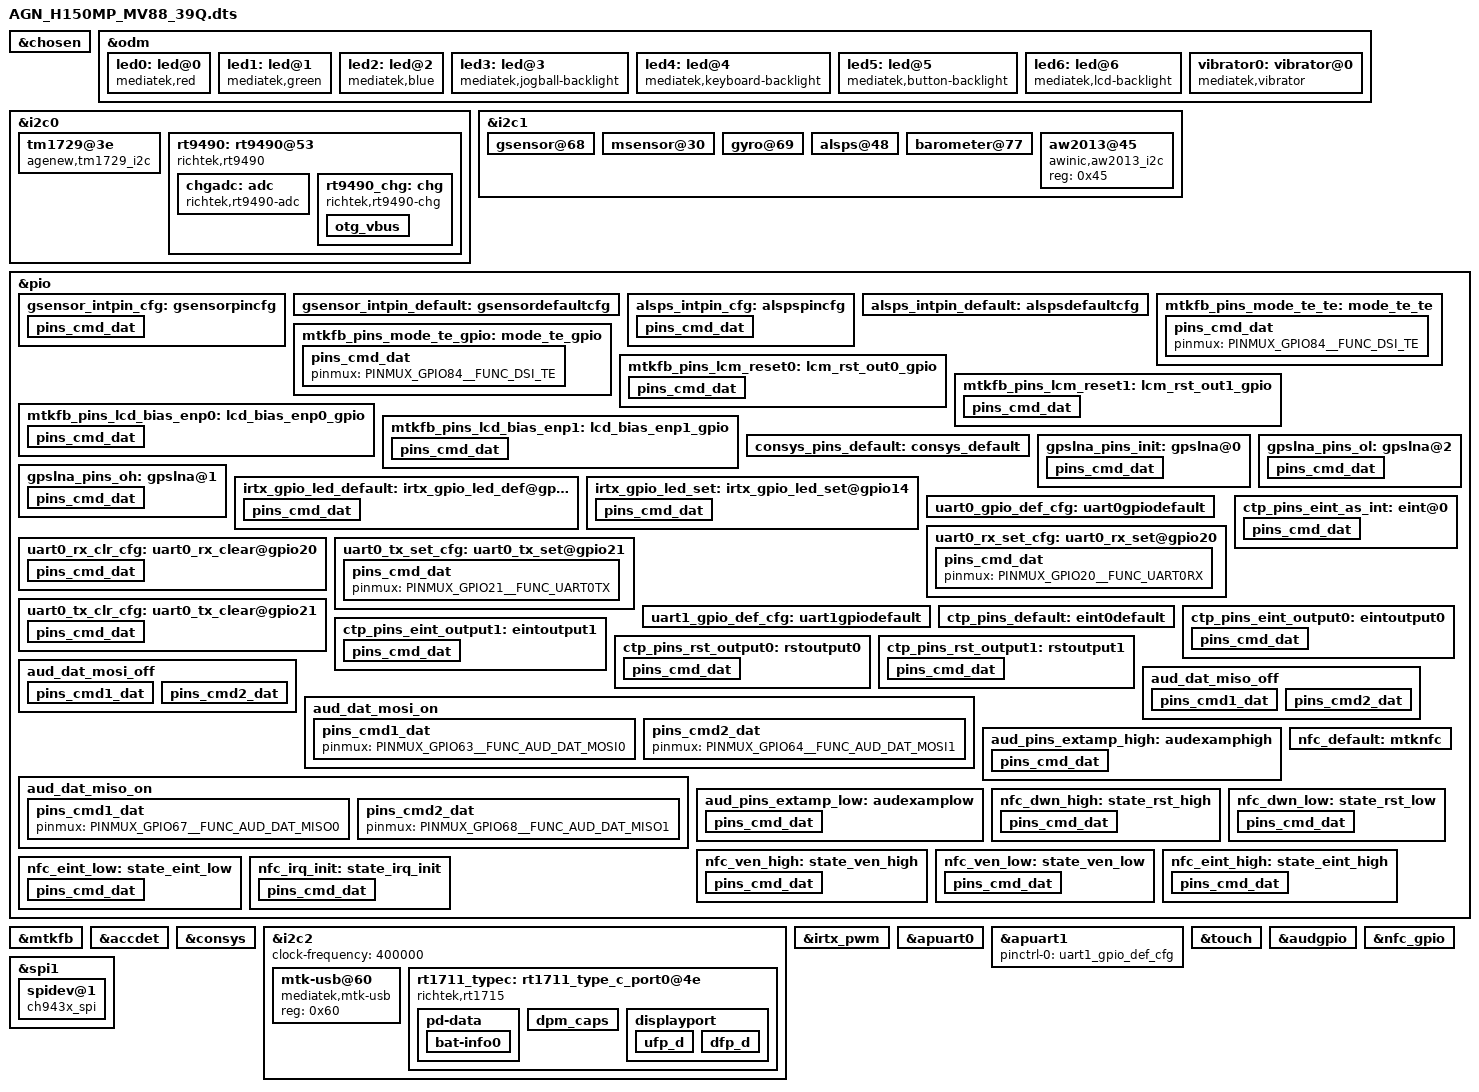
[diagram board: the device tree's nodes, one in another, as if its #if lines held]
/*
 * Mediatek's MT6739 SoC device tree source
 *
 * Copyright (C) 2016 MediaTek Inc.
 *
 * This program is free software; you can redistribute it and/or modify
 * it under the terms of the GNU General Public License version 2 as
 * published by the Free Software Foundation.
 *
 * This program is distributed in the hope that it will be useful,
 * but WITHOUT ANY WARRANTY; without even the implied warranty of
 * MERCHANTABILITY or FITNESS FOR A PARTICULAR PURPOSE.
 * See http://www.gnu.org/licenses/gpl-2.0.html for more details.
 */
#include <generated/autoconf.h>
/dts-v1/;

/plugin/;
#include <dt-bindings/mmc/mt6739-msdc.h>
#include <dt-bindings/iio/adc/richtek,rt9490-adc.h>
#include <dt-bindings/pinctrl/mt6739-pinfunc.h>
#include <dt-bindings/interrupt-controller/irq.h>
#include <dt-bindings/mfd/richtek,rt9490.h>
#include <dt-bindings/interrupt-controller/arm-gic.h>
#include <dt-bindings/gpio/gpio.h>

#define __THIS_PIN_IS_UNUSED_GPIO_NUM__                  (2)   //The board does not use this GPIO
#define __THIS_PIN_IS_UNUSED_GPIO__                      PINMUX_GPIO2__FUNC_GPIO2 //The board does not use this GPIO


/* chosen */
&chosen {
	/* fpga may has no lk, we need to specify display info here */
	/* fb buffer is reserved using this dts by memory node above */

	atag,videolfb-fb_base_l = <0x5e605000>;
	atag,videolfb-fb_base_h = <0>;
	atag,videolfb-islcmfound = <1>;
	atag,videolfb-islcm_inited = <0>;
	atag,videolfb-fps= <6000>;
	atag,videolfb-vramSize= <0x017bb000>;
	atag,videolfb-lcmname= "nt35521_hd_dsi_vdo_truly_nt50358_drv";
};

&odm {
	led0:led@0 {
		compatible = "mediatek,red";
		led_mode = <3>;
		data = <1>;
		pwm_config = <0 0 0 0 0>;
	};
	led1:led@1 {
		compatible = "mediatek,green";
		led_mode = <3>;
		data = <2>;
		pwm_config = <0 0 0 0 0>;
	};
	led2:led@2 {
		compatible = "mediatek,blue";
		led_mode = <0>;
		data = <1>;
		pwm_config = <0 0 0 0 0>;
	};
	led3:led@3 {
		compatible = "mediatek,jogball-backlight";
		led_mode = <0>;
		data = <1>;
		pwm_config = <0 0 0 0 0>;
	};
	led4:led@4 {
		compatible = "mediatek,keyboard-backlight";
                led_mode = <2>;//MT65XX_LED_MODE_GPIO
                data = <2>;    //aw9523b 
                pwm_config = <4 14 1 0 0>;//notes: led4, 14-AWEX_P1_6, off, reserve ...
	};
	led5:led@5 {
		compatible = "mediatek,button-backlight";
		led_mode = <0>;
		data = <1>;
		pwm_config = <0 0 0 0 0>;
	};
	led6:led@6 {
		compatible = "mediatek,lcd-backlight";
		led_mode = <5>;
		data = <1>;
		pwm_config = <0 2 0 0 0>;
	};
	vibrator0:vibrator@0 {
		compatible = "mediatek,vibrator";
		vib_timer = <25>;
		vib_limit = <9>;
		vib_vol= <9>;
	};
};

&i2c0 {
    tm1729@3e {
            compatible = "agenew,tm1729_i2c";
            reg = <0x3e>;
            lcd-3v3-en = <&pio 96 0x0>;
			tp-i2c-sda = <&pio 128 0x0>;
			tp-i2c-scl = <&pio 129 0x0>;	
    };
	
	rt9490: rt9490@53 {
		compatible = "richtek,rt9490";
		reg = <0x53>;
		interrupt-parent = <&pio>;
		interrupts = <9 IRQ_TYPE_EDGE_FALLING 9 0>;
		interrupt-controller;
		#interrupt-cells = <1>;

		chgadc: adc {
			compatible = "richtek,rt9490-adc";
			#io-channel-cells = <1>;
		};

		rt9490_chg: chg {
			compatible = "richtek,rt9490-chg";//在 DTS 文件中增加驱动的资源描述
			interrupts = <RT9490_IRQ_VAC1PG>, <RT9490_IRQ_WDT>,
				     <RT9490_IRQ_AICC>, <RT9490_IRQ_BC12DN>,
				     <RT9490_IRQ_CHG>;
			interrupt-names = "vbus-rdy", "wdt", "aicc",
					  "bc12-done", "chg-stat";
			richtek,cv-microvolt = <8900000>;
			ceb-gpio = <&pio 94 GPIO_ACTIVE_LOW>;
			szb-gpio = <&pio 101 GPIO_ACTIVE_LOW>;//新增
			usbsw-gpio = <&pio 12 GPIO_ACTIVE_HIGH>;
			io-channels = <&chgadc RT9490_CHAN_TDIE>,
				      <&chgadc RT9490_CHAN_TS>,
				      <&chgadc RT9490_CHAN_VSYS>,
				      <&chgadc RT9490_CHAN_VBAT>,
				      <&chgadc RT9490_CHAN_VBUS>,
				      <&chgadc RT9490_CHAN_IBAT>,
				      <&chgadc RT9490_CHAN_IBUS>,
				      <&chgadc RT9490_CHAN_VAC1>,
				      <&chgadc RT9490_CHAN_VAC2>,
				      <&chgadc RT9490_CHAN_DM>,
				      <&chgadc RT9490_CHAN_DP>;
			io-channel-names = "TDIE", "TS", "VSYS", "VBAT", "VBUS",
					   "IBAT", "IBUS", "VAC1", "VAC2", "DM",
					   "DP";
			chg_name = "primary_chg";
			otg_vbus {
				regulator-name = "rt9490-otg-vbus";
				regulator-min-microvolt = <2800000>;
				regulator-max-microvolt = <22000000>;
			};
		};
	};
};

&i2c1 {
/*  start sensor */
	gsensor@68 {
		pinctrl-names = "pin_default", "pin_cfg";
		pinctrl-0 = <&gsensor_intpin_default>;
		pinctrl-1 = <&gsensor_intpin_cfg>;
		i2c_num	= <1>;
		direction = <0>;
		power_id = <0xffff>;
		power_vol = <0>;
		firlen = <16>;
		is_batch_supported = <0>;
	};

	msensor@30 {
		i2c_num = <1>;
		i2c_addr = <0x30 0 0 0>;
		direction = <1>;
		power_id = <0xffff>;
		power_vol = <0>;
		is_batch_supported = <0>;
	};

	gyro@69 {
//		pinctrl-names = "pin_default", "pin_cfg";
//		pinctrl-0 = <&gyro_intpin_default>;
//		pinctrl-1 = <&gyro_intpin_cfg>;
		i2c_num = <0>;
		i2c_addr = <0x69 0 0 0>;
		direction = <2>;
		power_id = <0xffff>;
		power_vol = <0>;
		firlen = <0>;
		is_batch_supported = <0>;
	};

	alsps@48 {
		pinctrl-names = "pin_default", "pin_cfg";
		pinctrl-0 = <&alsps_intpin_default>;
		pinctrl-1 = <&alsps_intpin_cfg>;
		status = "okay";
		/* customization */
		i2c_num = <1>;
		i2c_addr = <0x48 0 0 0>;
		polling_mode_ps = <0>;
		polling_mode_als = <1>;
		power_id = <0xffff>;
		power_vol = <0>;
		als_level = <0 328 861 1377 3125 7721 7767 12621 23062 28430
				33274 47116 57694 57694 65535>;
		als_value = <0 133 304 502 1004 2005 3058 5005 8008 10010
				12000 16000 20000 20000 20000 20000>;
		ps_threshold_high = <26>;
		ps_threshold_low = <21>;
		is_batch_supported_ps = <0>;
		is_batch_supported_als = <0>;
	};

	barometer@77 {
		i2c_num = <1>;
		i2c_addr = <0x77 0 0 0>;
		direction = <0>;
		power_id = <0xffff>;
		power_vol = <0>;
		firlen = <32>;
		is_batch_supported = <0>;
	};
/* end sensor */

    aw2013@45{
           compatible = "awinic,aw2013_i2c";
           reg = <0x45>;
           status = "okay";
	};

};

/* sensor gpio standization */

&pio {

	gsensor_intpin_cfg: gsensorpincfg {

	    pins_cmd_dat {
			pinmux = <PINMUX_GPIO9__FUNC_GPIO9>;
			slew-rate = <0>;
			bias-pull-down = <00>;
		};
	};

	gsensor_intpin_default: gsensordefaultcfg {

	};
};


&pio {
	alsps_intpin_cfg: alspspincfg {

		pins_cmd_dat {
			pinmux = <PINMUX_GPIO6__FUNC_GPIO6>;
			slew-rate = <0>;
			//bias-pull-up = <MTK_PUPD_SET_R1R0_01>;
			bias-pull-up = <00>;
		};
	};

	alsps_intpin_default: alspsdefaultcfg {

	};
};

/* sensor end */

/* DISPSYS GPIO standardization */
&pio {
	mtkfb_pins_mode_te_gpio: mode_te_gpio {
		pins_cmd_dat {
			pinmux = <PINMUX_GPIO84__FUNC_DSI_TE>;
		};
	};

	mtkfb_pins_mode_te_te: mode_te_te {
		pins_cmd_dat {
			pinmux = <PINMUX_GPIO84__FUNC_DSI_TE>;
		};
	};

	mtkfb_pins_lcm_reset0: lcm_rst_out0_gpio {
		pins_cmd_dat {
			pinmux = <PINMUX_GPIO83__FUNC_LCM_RST>;
			slew-rate = <1>;
			output-low;
		};
	};

	mtkfb_pins_lcm_reset1: lcm_rst_out1_gpio {
		pins_cmd_dat {
			pinmux = <PINMUX_GPIO83__FUNC_LCM_RST>;
			slew-rate = <1>;
			output-high;
		};
	};

	mtkfb_pins_lcd_bias_enp0: lcd_bias_enp0_gpio {
		pins_cmd_dat {
			pinmux = <PINMUX_GPIO163__FUNC_GPIO163>;
			slew-rate = <1>;
			output-low;
		};
	};
	mtkfb_pins_lcd_bias_enp1: lcd_bias_enp1_gpio {
		pins_cmd_dat {
			pinmux = <PINMUX_GPIO163__FUNC_GPIO163>;
			slew-rate = <1>;
			output-high;
		};
	};

};

&mtkfb {
	pinctrl-names = "mode_te_gpio", "mode_te_te", "lcm_rst_out0_gpio",
		"lcm_rst_out1_gpio", "lcd_bias_enp0_gpio", "lcd_bias_enp1_gpio";
	pinctrl-0 = <&mtkfb_pins_mode_te_gpio>;
	pinctrl-1 = <&mtkfb_pins_mode_te_te>;
	pinctrl-2 = <&mtkfb_pins_lcm_reset0>;
	pinctrl-3 = <&mtkfb_pins_lcm_reset1>;
	pinctrl-4 = <&mtkfb_pins_lcd_bias_enp0>;
	pinctrl-5 = <&mtkfb_pins_lcd_bias_enp1>;
	status = "okay";
};
/* DISPSYS GPIO standardization end */


/* accdet start */
&accdet {
	/* accdet micbias voltage: 0x07,2.7v;0x05,2.5v;0x02,1.9v */
	accdet-mic-vol = <6>;
	headset-mode-setting = <0x500 0x500 1 0x1f0 0x800 0x800 0x20 0x44>;
	accdet-plugout-debounce = <1>;
	/*1:ACC mode, 2:low cost without in bias, 6:low cost with in bias*/
	accdet-mic-mode = <2>;
/* eint_level_trigger: 8,LEVEL_LOW(default);4,LEVEL_HIGH;others,LEVEL_LOW */
	headset-eint-level-pol = <8>;
	/*0--MD_MAX--UP_MAX--DW_MAX*/
	headset-three-key-threshold = <0 80 220 400>;
	headset-three-key-threshold-CDD = <0 121 192 600>;
	/*0--MD_MAX--VOICE_MAX--UP_MAX--DW_MAX*/
	headset-four-key-threshold = <0 58 121 192 400>;
	status = "okay";
};
/* accdet end */

/* CONSYS GPIO standardization */
&pio {
	consys_pins_default: consys_default {
	};
	gpslna_pins_init: gpslna@0 {
		pins_cmd_dat {
			pinmux = <PINMUX_GPIO15__FUNC_GPIO15>;
			slew-rate = <0>;
			bias-disable;
			output-low;
		};
	};
	gpslna_pins_oh: gpslna@1 {
		pins_cmd_dat {
			pinmux = <PINMUX_GPIO15__FUNC_GPIO15>;
			slew-rate = <1>;
			output-high;
		};
	};
	gpslna_pins_ol: gpslna@2 {
		pins_cmd_dat {
			pinmux = <PINMUX_GPIO15__FUNC_GPIO15>;
			slew-rate = <1>;
			output-low;
		};
	};
};
&consys {
	pinctrl-names = "default", "gps_lna_state_init",
			"gps_lna_state_oh", "gps_lna_state_ol";
	pinctrl-0 = <&consys_pins_default>;
	pinctrl-1 = <&gpslna_pins_init>;
	pinctrl-2 = <&gpslna_pins_oh>;
	pinctrl-3 = <&gpslna_pins_ol>;
	status = "okay";
};

&i2c2 {
	#address-cells = <1>;
	#size-cells = <0>;
	clock-frequency = <400000>;

	mtk-usb@60 {
		compatible = "mediatek,mtk-usb";
		reg = <0x60>;
		status = "okay";
	};
	
	rt1711_typec: rt1711_type_c_port0@4e {
		compatible = "richtek,rt1715";
		reg = <0x4e>;
		status = "okay";
		tcpc-dual,supported_modes = <0>; /* 0: dfp/ufp, */
						 /* 1: dfp, 2: ufp */
		rt-tcpc,name = "type_c_port0"; /* tcpc_device's name */
		/* 0: Unknown, 1: SNK, 2: SRC, 3: DRP, 4: Try.SRC, 5: Try.SNK*/
		rt-tcpc,role_def = <5>;
		/* 0: Default, 1: 1.5, 2: 3.0 */
		rt-tcpc,rp_level = <0>;
		/* 0: Never, 1: Always, 2: EMarkOnly, 3: StartOnly */
		rt-tcpc,vconn_supply  = <2>;
#if (CONFIG_MTK_GAUGE_VERSION == 30)
		rt-tcpc,notifier_supply_num = <3>;
#else
		rt-tcpc,notifier_supply_num = <2>;
#endif
		rt1711pd,intr_gpio = <&pio 50 0x0>;
		rt1711pd,intr_gpio_num = <50>;

		pd-data {
			pd,vid = <0x29cf>;
			pd,pid = <0x1711>;
			pd,source-cap-ext = /bits/ 8 <0xcf 0x29 0x11 0x17
						      0x00 0x00 0x00 0x00
						      0x00 0x00 0x00 0x00
						      0x00 0x00 0x00 0x00
						      0x00 0x00 0x00 0x00
						      0x00 0x00 0x01 0x02
						      0x00>;
			pd,mfrs = "RichtekTCPC";

			/*
			 *	VSAFE5V = 0, MAX_POWER = 1, CUSTOM = 2,
			 *	MAX_POWER_LV = 0x21, MAX_POWER_LVIC = 0x31
			 *	MAX_POWER_HV = 0x41, MAX_POWER_HVIC = 0x51
			 */
			pd,charging_policy= <0x31>;

			/*
			 * Fixed 5V, 500 mA <0x00019032>
			 * Fixed 5V, 1A <0x00019064>
			 * Fixed 5V, 2A <0x000190c8>
			 * Fixed 5V, 3A <0x0001912c>
			 * Fixed 9V, 500 mA <0x0002d032>
			 * Fixed 9V, 1A <0x0002d064>
			 * Fixed 9V, 2A <0x0002d0c8>
			 * Fixed 9V, 3A <0x0002d12c>
			 * Variable 5-9V, 1A <0x8642d064>
			 * Variable 5-9V, 2A <0x8642d0c8>
			 * Variable 5-9V, 3A <0x8642d12c>
			 * PPS 3V~5.9V, 3A <0xC0761E3C>
			 */
			pd,source-pdo-size = <1>;
			pd,source-pdo-data = <0x00019032>;
			pd,sink-pdo-size = <2>;
			pd,sink-pdo-data = <0x000190c8>;

			/*
			 * No DP, host + device
			 *	pd,id-vdo-size = <6>;
			 *	pd,id-vdo-data = <0xd14029cf 0x0 0x17110000
						  0x61000000 0x0 0x41000000>;
			 * With DP
			 *	pd,id-vdo-size = <6>;
			 *	pd,id-vdo-data = <0xd54029cf 0x0 0x17110000
						  0x61000000 0x0 0x41000000>;
			 */

			 pd,id-vdo-size = <6>;
			 pd,id-vdo-data = <0xd14029cf 0x0 0x17110000
					   0x61000000 0x0 0x41000000>;

			bat,nr = <1>;
			pd,country_nr = <0>;

			bat-info0 {
				bat,vid = <0x29cf>;
				bat,pid = <0x1711>;
				bat,mfrs = "bat1";
				bat,design_cap = <3000>;
			};

			//bat-info1 {
			//	bat,vid = <0x8abc>;
			//	bat,pid = <0x5234>;
			//	bat,mfrs = "bat2";
			//	bat,design_cap = <4000>;
			//};

			//country0 {
			//	pd,country_code = <0x5457>;
			//	pd,country_len = <2>; /* max len = 26 */
			//	pd,country_data = <0xff 0xff>;
			//};

			//country1 {
			//	pd,country_code = <0x5553>;
			//	pd,country_len = <3>; /* max len = 26 */
			//	pd,country_data = <0xf1 0xf2 0xf3>;
			//};
		};
		dpm_caps {
			local_dr_power;
			local_dr_data;
			//local_ext_power;
			local_usb_comm;
			//local_usb_suspend;
			//local_high_cap;
			//local_give_back;
			local_no_suspend;
			local_vconn_supply;

			//attemp_discover_cable_dfp;
			attemp_enter_dp_mode;
			attemp_discover_cable;
			attemp_discover_id;

			/* 0: disable, 1: prefer_snk, 2: prefer_src */
			pr_check = <0>;
			//pr_reject_as_source;
			//pr_reject_as_sink;
			//pr_check_gp_source;
			//pr_check_gp_sink;

			/* 0: disable, 1: prefer_ufp, 2: prefer_dfp */
			dr_check = <0>;
			//dr_reject_as_dfp;
			//dr_reject_as_ufp;
		};
		displayport {
			/* connection type = "both", "ufp_d", "dfp_d" */
			1st_connection = "dfp_d";
			2nd_connection = "dfp_d";
			signal,dp_v13;
			//signal,dp_gen2;
			usbr20_not_used;
			typec,receptacle;
			ufp_d {
				//pin_assignment,mode_a;
				//pin_assignment,mode_b;
				//pin_assignment,mode_c;
				//pin_assignment,mode_d;
				//pin_assignment,mode_e;
			};
			dfp_d {
				/* Only support mode C & D */
				//pin_assignment,mode_a;
				//pin_assignment,mode_b;
				pin_assignment,mode_c;
				pin_assignment,mode_d;
				pin_assignment,mode_e;
				pin_assignment,mode_f;
			};
		};
	};
};

/* IRTX GPIO Start */
&irtx_pwm {
	pinctrl-names = "irtx_gpio_led_default", "irtx_gpio_led_set";
	pinctrl-0 = <&irtx_gpio_led_default>;
	pinctrl-1 = <&irtx_gpio_led_set>;
	status = "okay";
};
&pio {
	/* IRTX GPIO Settings -Start */
	/* default: GPIO0, output, high */
	irtx_gpio_led_default:irtx_gpio_led_def@gpio14 {
		pins_cmd_dat {
			pinmux = <PINMUX_GPIO14__FUNC_GPIO14>;
			slew-rate = <1>;
			bias-disable;
			output-low;
			input-schmitt-enable = <0>;
		};
	};

	irtx_gpio_led_set:irtx_gpio_led_set@gpio14 {
		pins_cmd_dat {
			pinmux = <PINMUX_GPIO14__FUNC_PWM0>;
			slew-rate = <1>;
			output-high;
		};
	};
}; /* IRTX GPIO Settings -End */

/* UART GPIO */
&apuart0 {
	pinctrl-names = "uart0_gpio_default",
			"uart0_rx_set",
			"uart0_rx_clear",
			"uart0_tx_set",
			"uart0_tx_clear";
	pinctrl-0 = <&uart0_gpio_def_cfg>;
	pinctrl-1 = <&uart0_rx_set_cfg>;
	pinctrl-2 = <&uart0_rx_clr_cfg>;
	pinctrl-3 = <&uart0_tx_set_cfg>;
	pinctrl-4 = <&uart0_tx_clr_cfg>;
	status = "okay";
};

&apuart1 {
	pinctrl-names = "uart1_gpio_default";
	pinctrl-0 = <&uart1_gpio_def_cfg>;
	status = "okay";
};

&pio {
	/* UART GPIO Settings - Start */
	/* UART0: rx set, rx clear, tx clear, tx clear*/
	uart0_gpio_def_cfg:uart0gpiodefault {

	};
	uart0_rx_set_cfg:uart0_rx_set@gpio20 {
		pins_cmd_dat {
			pinmux = <PINMUX_GPIO20__FUNC_UART0RX>;
		};
	};
	uart0_rx_clr_cfg:uart0_rx_clear@gpio20 {
		pins_cmd_dat {
			pinmux = <PINMUX_GPIO20__FUNC_GPIO20>;
			slew-rate = <1>;
			output-high;
		};
	};
	uart0_tx_set_cfg:uart0_tx_set@gpio21 {
		pins_cmd_dat {
			pinmux = <PINMUX_GPIO21__FUNC_UART0TX>;
		};
	};
	uart0_tx_clr_cfg:uart0_tx_clear@gpio21 {
		pins_cmd_dat {
			pinmux = <PINMUX_GPIO21__FUNC_GPIO21>;
			slew-rate = <1>;
			output-high;
		};
	};
	/* UART1: rx set, rx clear, tx clear, tx clear*/
	uart1_gpio_def_cfg:uart1gpiodefault {

	};
};/* UART GPIO end */

/* TOUCH start */
&touch {
	tpd-resolution = <480 960>;
	use-tpd-button = <1>;
	tpd-key-num = <3>;
	tpd-key-local= <139 172 158 0>;
	tpd-key-dim-local = <80 1350 100 40 320 1350 100 40 560 1350 100 40 0 0 0 0>; 
	tpd-max-touch-num = <5>;
	tpd-filter-enable = <0>;
	tpd-filter-pixel-density = <93>;
	tpd-filter-custom-prameters = <0 0 0 0 0 0 0 0 0 0 0 0>;
	tpd-filter-custom-speed = <0 0 0>;
	pinctrl-names = "default", "state_eint_as_int",
		"state_eint_output0", "state_eint_output1",
		"state_rst_output0", "state_rst_output1";
	pinctrl-0 = <&ctp_pins_default>;
	pinctrl-1 = <&ctp_pins_eint_as_int>;
	pinctrl-2 = <&ctp_pins_eint_output0>;
	pinctrl-3 = <&ctp_pins_eint_output1>;
	pinctrl-4 = <&ctp_pins_rst_output0>;
	pinctrl-5 = <&ctp_pins_rst_output1>;
	status = "okay";
};
&pio {
	ctp_pins_default: eint0default {
	};
	ctp_pins_eint_as_int: eint@0 {
		pins_cmd_dat {
			pinmux = <PINMUX_GPIO1__FUNC_GPIO1>;
			slew-rate = <0>;
			bias-disable;
		};
	};
	ctp_pins_eint_output0: eintoutput0 {
		pins_cmd_dat {
			pinmux = <PINMUX_GPIO1__FUNC_GPIO1>;
			slew-rate = <1>;
			output-low;
		};
	};
	ctp_pins_eint_output1: eintoutput1 {
		pins_cmd_dat {
			pinmux = <PINMUX_GPIO1__FUNC_GPIO1>;
			slew-rate = <1>;
			output-high;
		};
	};
	ctp_pins_rst_output0: rstoutput0 {
		pins_cmd_dat {
			pinmux = <PINMUX_GPIO108__FUNC_GPIO108>;
			slew-rate = <1>;
			output-low;
		};
	};
	ctp_pins_rst_output1: rstoutput1 {
		pins_cmd_dat {
			pinmux = <PINMUX_GPIO108__FUNC_GPIO108>;
			slew-rate = <1>;
			output-high;
		};
	};
};
/* TOUCH end */

/* AUDIO GPIO standardization */
&audgpio {
	pinctrl-names = "aud_dat_mosi_off",
			"aud_dat_mosi_on",
			"aud_dat_miso_off",
			"aud_dat_miso_on",
			"extamp-pullhigh",
			"extamp-pulllow";
	pinctrl-0 = <&aud_dat_mosi_off>;
	pinctrl-1 = <&aud_dat_mosi_on>;
	pinctrl-2 = <&aud_dat_miso_off>;
	pinctrl-3 = <&aud_dat_miso_on>;
	pinctrl-4 = <&aud_pins_extamp_high>;
	pinctrl-5 = <&aud_pins_extamp_low>;
	status = "okay";
};

&pio {
	aud_dat_mosi_off: aud_dat_mosi_off {
		pins_cmd1_dat {
			pinmux = <PINMUX_GPIO63__FUNC_GPIO63>;
			input-enable;
			slew-rate = <0>;
			bias-disable;
		};
		pins_cmd2_dat {
			pinmux = <PINMUX_GPIO64__FUNC_GPIO64>;
			input-enable;
			slew-rate = <0>;
			bias-disable;
		};
	};

	aud_dat_mosi_on: aud_dat_mosi_on {
		pins_cmd1_dat {
			pinmux = <PINMUX_GPIO63__FUNC_AUD_DAT_MOSI0>;
		};
		pins_cmd2_dat {
			pinmux = <PINMUX_GPIO64__FUNC_AUD_DAT_MOSI1>;
		};
	};

	aud_dat_miso_off: aud_dat_miso_off {
		pins_cmd1_dat {
			pinmux = <PINMUX_GPIO67__FUNC_GPIO67>;
			input-enable;
			slew-rate = <0>;
			bias-disable;
		};
		pins_cmd2_dat {
			pinmux = <PINMUX_GPIO68__FUNC_GPIO68>;
			input-enable;
			slew-rate = <0>;
			bias-disable;
		};
	};

	aud_dat_miso_on: aud_dat_miso_on {
		pins_cmd1_dat {
			pinmux = <PINMUX_GPIO67__FUNC_AUD_DAT_MISO0>;
		};
		pins_cmd2_dat {
			pinmux = <PINMUX_GPIO68__FUNC_AUD_DAT_MISO1>;
		};
	};
	aud_pins_extamp_high: audexamphigh {
		pins_cmd_dat {
			pinmux = <PINMUX_GPIO24__FUNC_GPIO24>;
			slew-rate = <1>;
			output-high;
		};
	};

	aud_pins_extamp_low: audexamplow {
		pins_cmd_dat {
			pinmux = <PINMUX_GPIO24__FUNC_GPIO24>;
			slew-rate = <1>;
			output-low;
		};
	};

};
/* AUDIO end */

/* NFC GPIO Settings -Start */
&nfc_gpio {      
    interrupt-parent = <&pio>;
    pinctrl-names = "mtknfc", "ven_high", "ven_low", "dwn_high", "dwn_low", "eint_high", "eint_low", "irq_init";
    pinctrl-0 = <&nfc_default>;
    pinctrl-1 = <&nfc_ven_high>;
    pinctrl-2 = <&nfc_ven_low>;
    pinctrl-3 = <&nfc_dwn_high>;
    pinctrl-4 = <&nfc_dwn_low>;
    pinctrl-5 = <&nfc_eint_high>;
    pinctrl-6 = <&nfc_eint_low>;
    pinctrl-7 = <&nfc_irq_init>;
};


/* NFC GPIO standardization */
&pio {
       nfc_default: mtknfc {

       };
       nfc_dwn_high: state_rst_high {
               pins_cmd_dat {
                       pinmux = <PINMUX_GPIO124__FUNC_GPIO124>;
                       slew-rate = <1>;
                       output-high;
               };
       };
       nfc_dwn_low: state_rst_low {
               pins_cmd_dat {
                       pinmux = <PINMUX_GPIO124__FUNC_GPIO124>;
                       slew-rate = <1>;
                       output-low;
               };
       };
       nfc_ven_high: state_ven_high {
               pins_cmd_dat {
                       pinmux = <PINMUX_GPIO118__FUNC_GPIO118>;
                       slew-rate = <1>;
                       output-high;
               };
       };
       nfc_ven_low: state_ven_low {
               pins_cmd_dat {
                       pinmux = <PINMUX_GPIO118__FUNC_GPIO118>;
                       slew-rate = <1>;
                       output-low;
               };
       };
       nfc_eint_high: state_eint_high {
               pins_cmd_dat {
                       pinmux = <PINMUX_GPIO7__FUNC_GPIO7>;
                       slew-rate = <1>;
                       output-high;
               };
       };
       nfc_eint_low: state_eint_low {
               pins_cmd_dat {
                       pinmux = <PINMUX_GPIO7__FUNC_GPIO7>;
                       slew-rate = <1>;
                       output-low;
               };
       };
       nfc_irq_init: state_irq_init {
               pins_cmd_dat {
                       pinmux = <PINMUX_GPIO7__FUNC_GPIO7>;
                       slew-rate = <0>;
                       bias-pull-down = <00>;
               };
       };
};
/* NFC GPIO Settings -End */

#if defined(CONFIG_AGENEW_SERIAL_CH9434)
&spi1 {
       status = "okay";
       #address-cells = <1>;
       #size-cells = <0>;
       spidev@1 {
               compatible = "ch943x_spi";
               reg = <0>;//CS0 pin//SPI1_A_CSB //chip_select
               spi-max-frequency = <5000000>;

               interrupt-parent = <&pio>;
               interrupts = <13 IRQ_TYPE_EDGE_FALLING 13 0>; //CH_INT GPIO13
			   
			   uart-3v3-en = <&pio 122 0x0>;
			   ir-vcc-en = <&pio 121 0x0>;
			   ir-en = <&pio 27 0x0>;
			   rfid-vcc-en = <&pio 6 0x0>;
			   rfid-gpio126 = <&pio 126 0x0>;	
			   scan-3v3-en = <&pio 117 0x0>;
			   scan-rst0 = <&pio 95 0x0>;
			   laser-en = <&pio 29 0x0>;
			   secure-en = <&pio 28 0x0>;
			   secure-rst = <&pio 112 0x0>;
			   
               status = "okay";
       };
};
#endif

#include <AGN_H150MP_MV88_39Q/cust.dtsi>
#include "cust_mt6739_camera.dtsi"
/*End of this file, DO NOT ADD ANYTHING HERE*/
